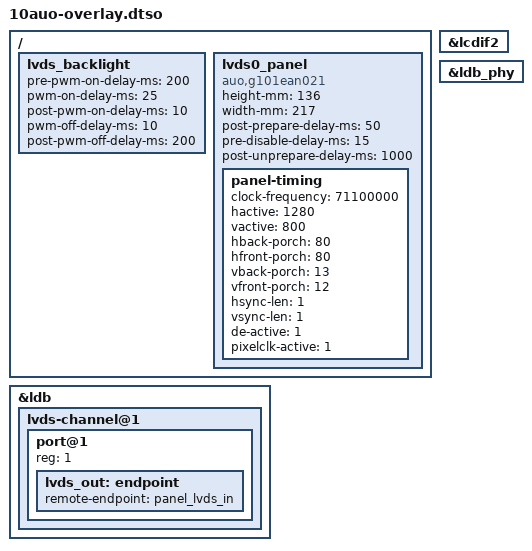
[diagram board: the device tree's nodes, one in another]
// SPDX-License-Identifier: (GPL-2.0+ OR MIT)
/*
 * Copyright 2023 ADLINK Technology Corp.
 *
 * Author: Po Cheng <po.cheng@adlinktech.com>
 */

/dts-v1/;
/plugin/;

/ {
	fragment@0 {
		target-path = "/";
		__overlay__ {
			lvds_backlight {
				pre-pwm-on-delay-ms = <200>;
				pwm-on-delay-ms = <25>;
				post-pwm-on-delay-ms = <10>;
				pwm-off-delay-ms = <10>;
				post-pwm-off-delay-ms = <200>;
				status = "okay";
			};
		};
	};

	fragment@1 {
		target-path = "/";
		__overlay__ {
			lvds0_panel {
				compatible = "auo,g101ean021", "panel-lvds";

				height-mm = <136>;
				width-mm = <217>;

				post-prepare-delay-ms = <50>;
				pre-disable-delay-ms = <15>;
				post-unprepare-delay-ms = <1000>;

				status = "okay";

				panel-timing {
					clock-frequency = <71100000>;
					hactive = <1280>;
					vactive = <800>;
					hback-porch = <80>;
					hfront-porch = <80>;
					vback-porch = <13>;
					vfront-porch = <12>;
					hsync-len = <1>;
					vsync-len = <1>;
					de-active = <1>;
					pixelclk-active = <1>;
				};
			};
		};
	};

	fragment@2 {
		target = <&ldb>;
		__overlay__ {
			status = "okay";
			lvds-channel@1 {
				#address-cells = <1>;
				#size-cells = <0>;
				status = "okay";
				port@1 {
					reg = <1>;

					lvds_out: endpoint {
						remote-endpoint = <&panel_lvds_in>;
					};
				};
			};
		};
	};

	fragment@3 {
		target = <&lcdif2>;
		__overlay__ {
			status = "okay";
		};
	};

	fragment@4 {
		target = <&ldb_phy>;
		__overlay__ {
			status = "okay";
		};
	};
};

